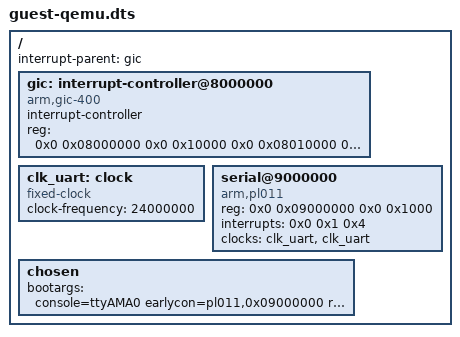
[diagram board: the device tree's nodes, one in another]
/dts-v1/;
/include/ "guest-base.dtsi"

// QEMU virt machine (-machine virt,gic-version=2)
// UART: 0x09000000  GIC: GICD 0x08000000 / GICC 0x08010000

/ {
	interrupt-parent = <&gic>;

	gic: interrupt-controller@8000000 {
		compatible = "arm,gic-400";
		#interrupt-cells = <3>;
		#address-cells = <0>;
		interrupt-controller;
		reg = <0x0 0x08000000 0x0 0x10000
		       0x0 0x08010000 0x0 0x20000
		       0x0 0x08030000 0x0 0x20000
		       0x0 0x08050000 0x0 0x20000>;
	};

	clk_uart: clock {
		compatible = "fixed-clock";
		#clock-cells = <0>;
		clock-frequency = <24000000>;
	};

	serial@9000000 {
		compatible = "arm,pl011", "arm,primecell";
		reg = <0x0 0x09000000 0x0 0x1000>;
		interrupts = <0x0 0x1 0x4>;
		clocks = <&clk_uart &clk_uart>;
		clock-names = "uartclk", "apb_pclk";
	};

	chosen {
		bootargs = "console=ttyAMA0 earlycon=pl011,0x09000000 root=/dev/ram0 rdinit=/sbin/init";
	};
};
